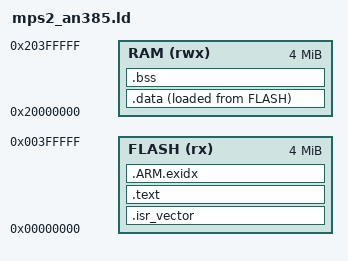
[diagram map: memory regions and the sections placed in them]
/* Memory map for the Arm MPS2 AN385 (Cortex-M3) as emulated by QEMU. */
MEMORY
{
    FLASH (rx)  : ORIGIN = 0x00000000, LENGTH = 4M
    RAM   (rwx) : ORIGIN = 0x20000000, LENGTH = 4M
}

ENTRY(Reset_Handler)

_estack = ORIGIN(RAM) + LENGTH(RAM);

SECTIONS
{
    .isr_vector :
    {
        KEEP(*(.isr_vector))
    } > FLASH

    .text :
    {
        *(.text*)
        *(.rodata*)
        KEEP(*(.init))
        KEEP(*(.fini))
        . = ALIGN(4);
    } > FLASH

    .ARM.exidx :
    {
        *(.ARM.exidx*)
    } > FLASH

    _sidata = LOADADDR(.data);

    .data :
    {
        . = ALIGN(4);
        _sdata = .;
        *(.data*)
        . = ALIGN(4);
        _edata = .;
    } > RAM AT > FLASH

    .bss (NOLOAD) :
    {
        . = ALIGN(4);
        _sbss = .;
        *(.bss*)
        *(COMMON)
        . = ALIGN(4);
        _ebss = .;
    } > RAM

    end = .;
    _end = .;
}
